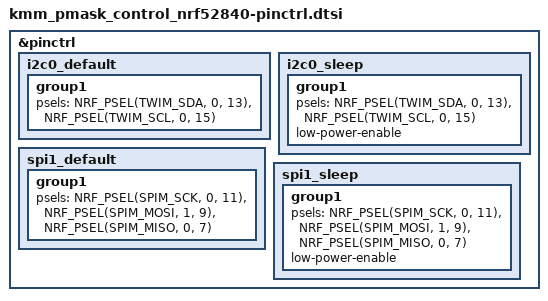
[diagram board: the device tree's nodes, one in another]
&pinctrl {
	/* I2C to the mask via PCA9517A repeater (EN = P0.14) */
	i2c0_default: i2c0_default {
		group1 {
			psels = <NRF_PSEL(TWIM_SDA, 0, 13)>,
				    <NRF_PSEL(TWIM_SCL, 0, 15)>;
		};
	};

	i2c0_sleep: i2c0_sleep {
		group1 {
			psels = <NRF_PSEL(TWIM_SDA, 0, 13)>,
				    <NRF_PSEL(TWIM_SCL, 0, 15)>;
			low-power-enable;
		};
	};

	/* microSD card, SPI mode */
	spi1_default: spi1_default {
		group1 {
			psels = <NRF_PSEL(SPIM_SCK, 0, 11)>,
				    <NRF_PSEL(SPIM_MOSI, 1, 9)>,
				    <NRF_PSEL(SPIM_MISO, 0, 7)>;
		};
	};

	spi1_sleep: spi1_sleep {
		group1 {
			psels = <NRF_PSEL(SPIM_SCK, 0, 11)>,
				    <NRF_PSEL(SPIM_MOSI, 1, 9)>,
				    <NRF_PSEL(SPIM_MISO, 0, 7)>;
			low-power-enable;
		};
	};
};
